# CY8C5888LTI_LP097 register map
File version: 0.1
CY8C58LP
Registers are 8-bit, read-write, no defined reset value unless marked. A register's access mark holds for its fields unless they carry their own. Offsets are from the block's base; lines under a group give offsets from that group; [hi:lo] are bit positions; {n}, {i} and the like mark numbered series; 'fields as' and 'values as' point back to an identical list; <NAME> marks a mode.

## Memory map
0x00000000 Buzzer_PWM
0x00000000 ADC_Battery — SAR ADC
0x00000000 Timer
0x00000000 Timer_IR
0x00000000 RTC
0x00000000 Control_Reg_1
0x00000000 Timer_R2
0x00000000 Timer_L2
0x00000000 Timer_L3
0x00000000 UART_1 — UART
0x00000000 PWM
0x00000000 I2C
0x00000000 Timer_L1
0x00000000 Timer_R3
0x00000000 Timer_R1

## Buzzer_PWM
Base 0x00000000
0x40006526 Buzzer_PWM_COMPARE_Reg 16-bit — UDB.D0 - Assigned Compare Value
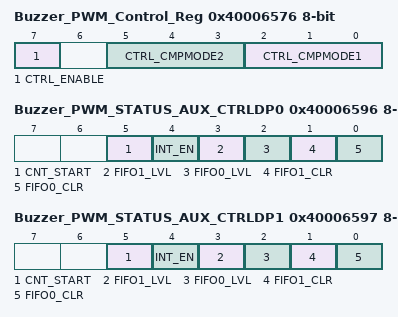
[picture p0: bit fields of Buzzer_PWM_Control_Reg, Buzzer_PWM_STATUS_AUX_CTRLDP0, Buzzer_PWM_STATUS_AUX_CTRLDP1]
0x40006576 Buzzer_PWM_Control_Reg — UDB Control Register - Assigned Control Register Value
  [7] CTRL_ENABLE — Enable the PWM
  [5:3] CTRL_CMPMODE2 — Compare mode 2
  [2:0] CTRL_CMPMODE1 — Compare mode 1
0x40006596 Buzzer_PWM_STATUS_AUX_CTRLDP0 — UDB Auxilliary Control Register
  [5] CNT_START — FIFO0 clear
    0=E_CNT_START0 (Disable counter); 1=E_CNT_START1 (Enable counter)
  [4] INT_EN
    0=E_INT_EN0 (Interrupt disabled); 1=E_INT_EN1 (Interrupt enabled)
  [3] FIFO1_LVL — FIFO level
    0=E_FIFO_LVL_0 (FIFO LVL: input mode: FIFO not full; output mode: FIFO not empty); 1=E_FIFO_LVL_1 (FIFO LVL: input mode: FIFO at least 1/2 empty; output mode: FIFO at least 1/2 full)
  [2] FIFO0_LVL — FIFO level
    values as FIFO1_LVL
  [1] FIFO1_CLR — FIFO1 clear
    0=E_FIFO_CLR_0 (Normal FIFO operation); 1=E_FIFO_CLR_1 (Clear FIFO state)
  [0] FIFO0_CLR — FIFO0 clear
    values as FIFO1_CLR
0x40006597 Buzzer_PWM_STATUS_AUX_CTRLDP1 — UDB Auxilliary Control Register
  fields as Buzzer_PWM_STATUS_AUX_CTRLDP0

## ADC_Battery — SAR ADC
Base 0x00000000
0x40004616 SAR_TR0 — SAR trim register
{0x40005908+i} SAR_CSR{i} (i=0..6) — SAR status and control register {i}
0x40005B28 SAR_SW0 — SAR Analog Routing Register 0
{0x40005B28+i} SAR_SW{i} (i=2..4) — SAR Analog Routing Register {i}
0x40005B2E SAR_SW6 — SAR Analog Routing Register 6
0x40005B2F SAR_CLK — SAR Clock Selection Register
0x40005BA2 SAR_WRK 16-bit — SAR working register

## Timer
Base 0x00000000
0x4000640E Timer_COUNTER 16-bit — UDB.A0 - Current Down Counter Value
0x4000642E Timer_PERIOD 16-bit — UDB.D0 - Assigned Period
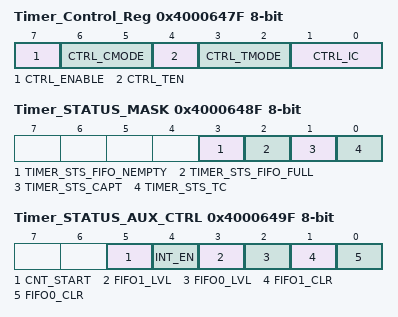
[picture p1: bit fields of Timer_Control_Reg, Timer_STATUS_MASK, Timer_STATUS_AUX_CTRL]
0x4000647F Timer_Control_Reg — UDB Control Register - Assigned Control Register Value
  [7] CTRL_ENABLE — Enable the Timer
  [6:5] CTRL_CMODE — Capture Mode
  [4] CTRL_TEN — Trigger Enable Bit
  [3:2] CTRL_TMODE — Trigger Mode
  [1:0] CTRL_IC — Interrupt Count
0x4000648F Timer_STATUS_MASK — UDB Status bits Interrupt Mask Enable Register
  [3] TIMER_STS_FIFO_NEMPTY ro — FIFO Empty status
  [2] TIMER_STS_FIFO_FULL ro — FIFO Full Status
  [1] TIMER_STS_CAPT ro — Enables the Interrupt on Capture
  [0] TIMER_STS_TC ro — Enables the Interrupt on TC
0x4000649F Timer_STATUS_AUX_CTRL — UDB Auxilliary Control Register
  [5] CNT_START — FIFO0 clear
    0=E_CNT_START0 (Disable counter); 1=E_CNT_START1 (Enable counter)
  [4] INT_EN
    0=E_INT_EN0 (Interrupt disabled); 1=E_INT_EN1 (Interrupt enabled)
  [3] FIFO1_LVL — FIFO level
    0=E_FIFO_LVL_0 (FIFO LVL: input mode: FIFO not full; output mode: FIFO not empty); 1=E_FIFO_LVL_1 (FIFO LVL: input mode: FIFO at least 1/2 empty; output mode: FIFO at least 1/2 full)
  [2] FIFO0_LVL — FIFO level
    values as FIFO1_LVL
  [1] FIFO1_CLR — FIFO1 clear
    0=E_FIFO_CLR_0 (Normal FIFO operation); 1=E_FIFO_CLR_1 (Clear FIFO state)
  [0] FIFO0_CLR — FIFO0 clear
    values as FIFO1_CLR

## Timer_IR
Base 0x00000000
0x40006407 Timer_IR_COUNTER 24-bit — UDB.A0 - Current Down Counter Value
0x40006427 Timer_IR_PERIOD 24-bit — UDB.D0 - Assigned Period
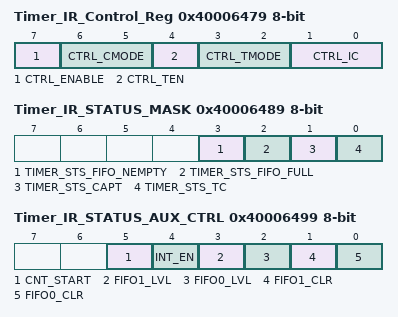
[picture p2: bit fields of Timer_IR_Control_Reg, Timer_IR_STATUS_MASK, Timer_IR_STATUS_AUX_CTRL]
0x40006479 Timer_IR_Control_Reg — UDB Control Register - Assigned Control Register Value
  [7] CTRL_ENABLE — Enable the Timer
  [6:5] CTRL_CMODE — Capture Mode
  [4] CTRL_TEN — Trigger Enable Bit
  [3:2] CTRL_TMODE — Trigger Mode
  [1:0] CTRL_IC — Interrupt Count
0x40006489 Timer_IR_STATUS_MASK — UDB Status bits Interrupt Mask Enable Register
  [3] TIMER_STS_FIFO_NEMPTY ro — FIFO Empty status
  [2] TIMER_STS_FIFO_FULL ro — FIFO Full Status
  [1] TIMER_STS_CAPT ro — Enables the Interrupt on Capture
  [0] TIMER_STS_TC ro — Enables the Interrupt on TC
0x40006499 Timer_IR_STATUS_AUX_CTRL — UDB Auxilliary Control Register
  [5] CNT_START — FIFO0 clear
    0=E_CNT_START0 (Disable counter); 1=E_CNT_START1 (Enable counter)
  [4] INT_EN
    0=E_INT_EN0 (Interrupt disabled); 1=E_INT_EN1 (Interrupt enabled)
  [3] FIFO1_LVL — FIFO level
    0=E_FIFO_LVL_0 (FIFO LVL: input mode: FIFO not full; output mode: FIFO not empty); 1=E_FIFO_LVL_1 (FIFO LVL: input mode: FIFO at least 1/2 empty; output mode: FIFO at least 1/2 full)
  [2] FIFO0_LVL — FIFO level
    values as FIFO1_LVL
  [1] FIFO1_CLR — FIFO1 clear
    0=E_FIFO_CLR_0 (Normal FIFO operation); 1=E_FIFO_CLR_1 (Clear FIFO state)
  [0] FIFO0_CLR — FIFO0 clear
    values as FIFO1_CLR
